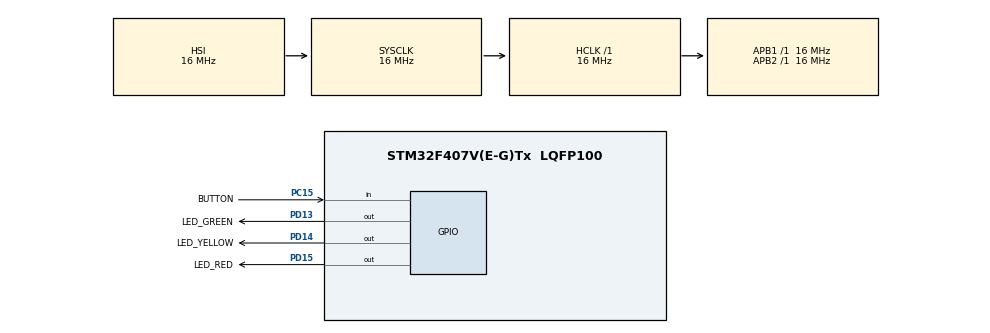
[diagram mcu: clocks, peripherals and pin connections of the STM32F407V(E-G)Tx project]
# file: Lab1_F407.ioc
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Mcu.Family=STM32F4
Mcu.Name=STM32F407V(E-G)Tx
Mcu.Package=LQFP100
NVIC.PriorityGroup=NVIC_PRIORITYGROUP_4
PA13.Mode=JTAG_5_pins
PA13.Signal=SYS_JTMS-SWDIO
PA14.Mode=JTAG_5_pins
PA14.Signal=SYS_JTCK-SWCLK
PA15.Mode=JTAG_5_pins
PA15.Signal=SYS_JTDI
PB3.Mode=JTAG_5_pins
PB3.Signal=SYS_JTDO-SWO
PB4.Mode=JTAG_5_pins
PB4.Signal=SYS_JTRST
PC15-OSC32_OUT.GPIO_Label=BUTTON
PC15-OSC32_OUT.GPIO_PuPd=GPIO_NOPULL
PC15-OSC32_OUT.Signal=GPIO_Input
PD13.GPIO_Label=LED_GREEN
PD13.GPIO_Speed=GPIO_SPEED_FREQ_LOW
PD13.PinState=GPIO_PIN_RESET
PD13.Signal=GPIO_Output
PD14.GPIO_Label=LED_YELLOW
PD14.GPIO_Speed=GPIO_SPEED_FREQ_LOW
PD14.PinState=GPIO_PIN_RESET
PD14.Signal=GPIO_Output
PD15.GPIO_Label=LED_RED
PD15.GPIO_Speed=GPIO_SPEED_FREQ_LOW
PD15.PinState=GPIO_PIN_RESET
PD15.Signal=GPIO_Output
ProjectManager.HeapSize=0x0
ProjectManager.StackSize=0x800
ProjectManager.TargetToolchain=STM32CubeIDE
RCC.AHBFreq_Value=16000000
RCC.APB1Freq_Value=16000000
RCC.APB1TimFreq_Value=16000000
RCC.APB2Freq_Value=16000000
RCC.APB2TimFreq_Value=16000000
RCC.CortexFreq_Value=16000000
RCC.HCLKFreq_Value=16000000
RCC.HSE_VALUE=25000000
RCC.HSI_VALUE=16000000
RCC.LSE_VALUE=32768
RCC.SYSCLKFreq_VALUE=16000000
board=custom

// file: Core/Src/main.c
/* SDK-1.1M Laboratory 1. Custom calls stay in CubeMX USER CODE regions. */
#include "main.h"
#include "gpio.h"
/* USER CODE BEGIN Includes */
#include "button.h"
#include "morse.h"
/* USER CODE END Includes */

void SystemClock_Config(void);

int main(void)
{
  HAL_Init();
  SystemClock_Config();
  MX_GPIO_Init();
  /* USER CODE BEGIN 2 */
  Button_Init(HAL_GetTick());
  Morse_Init();
  /* USER CODE END 2 */

  while (1)
  {
    /* USER CODE BEGIN 3 */
    uint32_t now_ms = HAL_GetTick();
    Button_Update(now_ms);
    Morse_Update(now_ms);
    __WFI(); /* SysTick wakes the CPU every millisecond. */
  }
  /* USER CODE END 3 */
}

void SystemClock_Config(void)
{
  RCC_OscInitTypeDef osc = {0};
  RCC_ClkInitTypeDef clock = {0};
  __HAL_RCC_PWR_CLK_ENABLE();
  __HAL_PWR_VOLTAGESCALING_CONFIG(PWR_REGULATOR_VOLTAGE_SCALE1);
  osc.OscillatorType = RCC_OSCILLATORTYPE_HSI;
  osc.HSIState = RCC_HSI_ON;
  osc.HSICalibrationValue = RCC_HSICALIBRATION_DEFAULT;
  osc.PLL.PLLState = RCC_PLL_NONE;
  if (HAL_RCC_OscConfig(&osc) != HAL_OK) Error_Handler();
  clock.ClockType = RCC_CLOCKTYPE_HCLK | RCC_CLOCKTYPE_SYSCLK |
                    RCC_CLOCKTYPE_PCLK1 | RCC_CLOCKTYPE_PCLK2;
  clock.SYSCLKSource = RCC_SYSCLKSOURCE_HSI;
  clock.AHBCLKDivider = RCC_SYSCLK_DIV1;
  clock.APB1CLKDivider = RCC_HCLK_DIV1;
  clock.APB2CLKDivider = RCC_HCLK_DIV1;
  if (HAL_RCC_ClockConfig(&clock, FLASH_LATENCY_0) != HAL_OK) Error_Handler();
}

void Error_Handler(void)
{
  /* USER CODE BEGIN Error_Handler_Debug */
  __disable_irq();
  for (;;) { __WFI(); } /* Fatal initialization failure; inspect with debugger. */
  /* USER CODE END Error_Handler_Debug */
}
